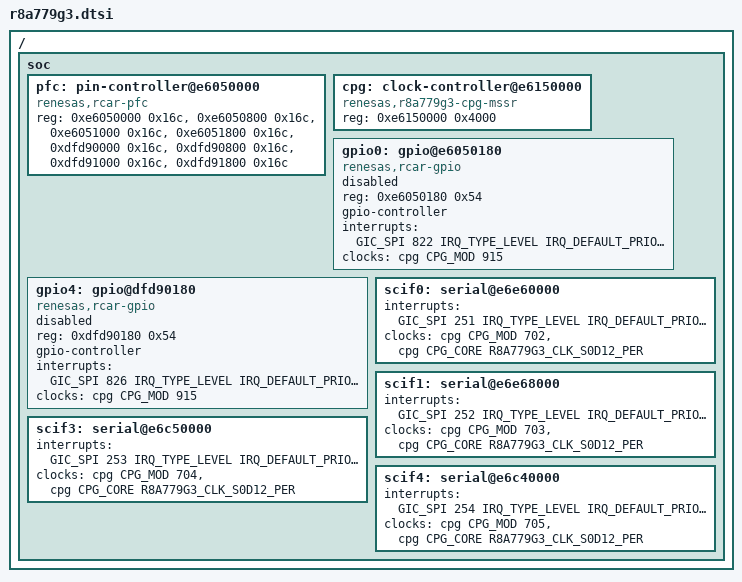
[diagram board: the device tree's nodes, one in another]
/*
 * Copyright (c) 2023 IoT.bzh
 *
 * SPDX-License-Identifier: Apache-2.0
 */

#include <renesas/rcar/gen4/rcar_gen4_cr52.dtsi>
#include <zephyr/dt-bindings/gpio/gpio.h>
#include <zephyr/dt-bindings/clock/r8a779g3_cpg_mssr.h>

/ {
	soc {
		pfc: pin-controller@e6050000 {
			compatible = "renesas,rcar-pfc";
			reg = <0xe6050000 0x16c>, <0xe6050800 0x16c>,
				  <0xe6051000 0x16c>, <0xe6051800 0x16c>,
				  <0xdfd90000 0x16c>, <0xdfd90800 0x16c>,
				  <0xdfd91000 0x16c>, <0xdfd91800 0x16c>;
		};

		/* Clock controller
		 * Using domain 0 as Linux
		 */
		cpg: clock-controller@e6150000 {
			compatible = "renesas,r8a779g3-cpg-mssr";
			reg = <0xe6150000 0x4000>;
			#clock-cells = <2>;
		};

		gpio0: gpio@e6050180 {
			compatible = "renesas,rcar-gpio";
			reg = <0xe6050180 0x54>;
			#gpio-cells = <2>;
			gpio-controller;
			interrupts = <GIC_SPI 822 IRQ_TYPE_LEVEL IRQ_DEFAULT_PRIORITY>;
			clocks = <&cpg CPG_MOD 915>;
			status = "disabled";
		};

		gpio4: gpio@dfd90180 {
			compatible = "renesas,rcar-gpio";
			reg = <0xdfd90180 0x54>;
			#gpio-cells = <2>;
			gpio-controller;
			interrupts = <GIC_SPI 826 IRQ_TYPE_LEVEL IRQ_DEFAULT_PRIORITY>;
			clocks = <&cpg CPG_MOD 915>;
			status = "disabled";
		};

		/* Linux console */
		scif0: serial@e6e60000 {
			interrupts = <GIC_SPI 251 IRQ_TYPE_LEVEL IRQ_DEFAULT_PRIORITY>;
			clocks = <&cpg CPG_MOD 702>, <&cpg CPG_CORE R8A779G3_CLK_S0D12_PER>;
		};

		/* Zephyr console */
		scif1: serial@e6e68000 {
			interrupts = <GIC_SPI 252 IRQ_TYPE_LEVEL IRQ_DEFAULT_PRIORITY>;
			clocks = <&cpg CPG_MOD 703>, <&cpg CPG_CORE R8A779G3_CLK_S0D12_PER>;
		};

		scif3: serial@e6c50000 {
			interrupts = <GIC_SPI 253 IRQ_TYPE_LEVEL IRQ_DEFAULT_PRIORITY>;
			clocks = <&cpg CPG_MOD 704>, <&cpg CPG_CORE R8A779G3_CLK_S0D12_PER>;
		};

		scif4: serial@e6c40000 {
			interrupts = <GIC_SPI 254 IRQ_TYPE_LEVEL IRQ_DEFAULT_PRIORITY>;
			clocks = <&cpg CPG_MOD 705>, <&cpg CPG_CORE R8A779G3_CLK_S0D12_PER>;
		};
	};
};
